AUTOSAR XML (schema 4-0-3)
standard types defined: Boolean, UInt32, UInt8
package /AUTOSAR_Platform/DataConstrs
  range DC_Boolean: raw 0..1
  range DC_UInt8: raw 0..255
package /PATAC/MSM/ComponentTypes
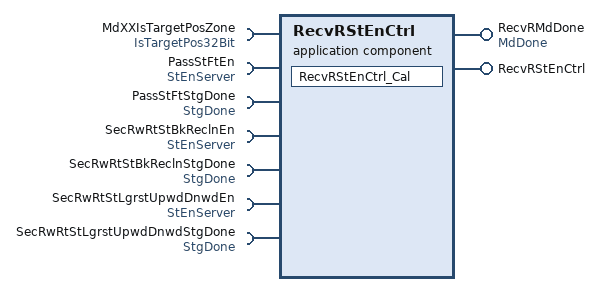
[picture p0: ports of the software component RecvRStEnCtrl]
  application sw component type RecvRStEnCtrl
    provide port RecvRMdDone: nonqueued-sender-com-spec{data-element=MdDone/Val, init-value=0}, provided-interface=MdDone
    provide port RecvRStEnCtrl: server-com-spec{operation=Cal, queue-length=1}, provided-interface=RecvRStEnCtrl
    7 x require port:
      MdXXIsTargetPosZone: nonqueued-receiver-com-spec{data-element=IsTargetPos32Bit/Val, filter=data-filter-type=ALWAYS, init-value=0}, required-interface=IsTargetPos32Bit
      PassStFtEn: required-com-specs=[Clear, Get, Set], required-interface=StEnServer
      PassStFtStgDone: nonqueued-receiver-com-spec{data-element=StgDone/Val, filter=data-filter-type=ALWAYS, init-value=0}, required-interface=StgDone
      SecRwRtStBkReclnEn: required-com-specs=[Clear, Get, Set], required-interface=StEnServer
      SecRwRtStBkReclnStgDone: nonqueued-receiver-com-spec{data-element=StgDone/Val, filter=data-filter-type=ALWAYS, init-value=0}, required-interface=StgDone
      SecRwRtStLgrstUpwdDnwdEn: required-com-specs=[Clear, Get, Set], required-interface=StEnServer
      SecRwRtStLgrstUpwdDnwdStgDone: nonqueued-receiver-com-spec{data-element=StgDone/Val, filter=data-filter-type=ALWAYS, init-value=0}, required-interface=StgDone
    behavior RecvRStEnCtrl_InternalBehavior
      operation invoked event OIT_RecvRStEnCtrl_Cal_RecvRStEnCtrl_Cal: start-on-event=RecvRStEnCtrl_Cal, operation=RecvRStEnCtrl.Cal
      runnable RecvRStEnCtrl_Cal
        data-receive-point-by-arguments:
          4 x access:
            REC_MdXXIsTargetPosZone_Val: accessed-variable=MdXXIsTargetPosZone.Val
            REC_PassStFtStgDone_Val: accessed-variable=PassStFtStgDone.Val
            REC_SecRwRtStBkReclnStgDone_Val: accessed-variable=SecRwRtStBkReclnStgDone.Val
            REC_SecRwRtStLgrstUpwdDnwdStgDone_Val: accessed-variable=SecRwRtStLgrstUpwdDnwdStgDone.Val
        data-send-points:
          access SEND_RecvRMdDone_Val: accessed-variable=RecvRMdDone.Val
        6 x sync call, all with timeout=0:
          SC_PassStFtEn_Clear: operation=PassStFtEn.Clear
          SC_PassStFtEn_Set: operation=PassStFtEn.Set
          SC_SecRwRtStBkReclnEn_Clear: operation=SecRwRtStBkReclnEn.Clear
          SC_SecRwRtStBkReclnEn_Set: operation=SecRwRtStBkReclnEn.Set
          SC_SecRwRtStLgrstUpwdDnwdEn_Clear: operation=SecRwRtStLgrstUpwdDnwdEn.Clear
          SC_SecRwRtStLgrstUpwdDnwdEn_Set: operation=SecRwRtStLgrstUpwdDnwdEn.Set
  swc implementation RecvRStEnCtrl_Implementation: behavior=RecvRStEnCtrl_InternalBehavior
    code-descriptors:
      code Default: artifact-descriptors=autosar-engineering-object={short-label=Default, category=SWSRC}
package /PATAC/MSM/ModeAdjust/PortInterface
  client server interface RecvRStEnCtrl
    operation Cal
  client server interface StEnServer
    operation Clear
      arg data: type=UInt8, direction=IN, server-argument-impl-policy=USE-ARGUMENT-TYPE
    operation Get
      arg data: type=UInt32, direction=OUT, server-argument-impl-policy=USE-ARGUMENT-TYPE
    operation Set
      arg data: type=UInt8, direction=IN, server-argument-impl-policy=USE-ARGUMENT-TYPE
  sender receiver interface IsTargetPos32Bit: invalidation-policy{data-element=IsTargetPos32Bit/Val, handle-invalid=DONT-INVALIDATE}
    data Val: type=UInt32
  sender receiver interface MdDone: invalidation-policy{data-element=MdDone/Val, handle-invalid=DONT-INVALIDATE}
    data Val: type=UInt8
  sender receiver interface StgDone: invalidation-policy{data-element=StgDone/Val, handle-invalid=DONT-INVALIDATE}
    data Val: type=Boolean
